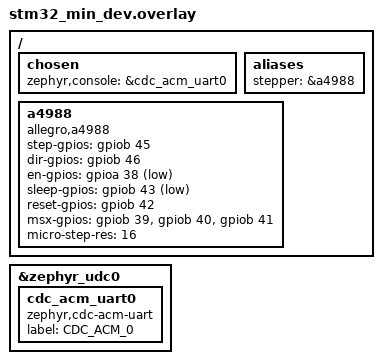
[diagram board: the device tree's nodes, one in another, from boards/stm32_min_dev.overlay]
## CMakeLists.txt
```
# SPDX-FileCopyrightText: Copyright (c) 2025 Marvin Ouma
# SPDX-License-Identifier: Apache-2.0

cmake_minimum_required(VERSION 3.20.0)

find_package(Zephyr REQUIRED HINTS $ENV{ZEPHYR_BASE})
project(a4988)

FILE(GLOB app_sources src/*.c)
target_sources(app PRIVATE ${app_sources})
```

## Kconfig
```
# SPDX-FileCopyrightText: Copyright (c) 2025 Marvin Ouma
# SPDX-License-Identifier: Apache-2.0

mainmenu "A4988 sample application"

config STEPS_PER_REV
       int "Steps per revolution"
       default 200


source "Kconfig.zephyr"
```

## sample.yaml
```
sample:
  name: A4988 Stepper Sample

tests:
  sample.stepper.a4988:
    harness: stepper
    tags: stepper
```

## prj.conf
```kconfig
CONFIG_STDOUT_CONSOLE=y
CONFIG_USB_DEVICE_STACK=y
CONFIG_USB_DEVICE_PRODUCT="Zephyr CDC ACM sample"
CONFIG_USB_DEVICE_PID=0x0001
CONFIG_LOG=y
CONFIG_USB_DRIVER_LOG_LEVEL_ERR=y
CONFIG_USB_DEVICE_LOG_LEVEL_ERR=y
CONFIG_SERIAL=y
CONFIG_UART_INTERRUPT_DRIVEN=y
CONFIG_UART_LINE_CTRL=y
CONFIG_USB_DEVICE_INITIALIZE_AT_BOOT=n

CONFIG_STEPPER=y
CONFIG_STEP_DIR_STEPPER_COUNTER_TIMING=y
```

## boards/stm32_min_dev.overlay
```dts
/ {

	chosen {
	       zephyr,console=&cdc_acm_uart0;
	};

	aliases {
		stepper = &a4988;
	};

	a4988: a4988 {
		compatible = "allegro,a4988";
		status = "okay";

		step-gpios = <&gpiob 45 GPIO_ACTIVE_HIGH>;
		dir-gpios = <&gpiob 46 GPIO_ACTIVE_HIGH>;
		en-gpios = <&gpioa 38 GPIO_ACTIVE_LOW>;
		sleep-gpios = <&gpiob 43 GPIO_ACTIVE_LOW>;
		reset-gpios = <&gpiob 42 GPIO_ACTIVE_HIGH>;
		msx-gpios = <&gpiob 39 GPIO_ACTIVE_HIGH>,
		            <&gpiob 40 GPIO_ACTIVE_HIGH>,
		            <&gpiob 41 GPIO_ACTIVE_HIGH>;
		micro-step-res = <16>;
	};
};

&zephyr_udc0 {
	     cdc_acm_uart0: cdc_acm_uart0 {
	     	compatible = "zephyr,cdc-acm-uart";
		label = "CDC_ACM_0";
	     };
};
```

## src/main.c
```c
/*
 * SPDX-FileCopyrightText: Copyright (c) 2025 Marvin Ouma
 * SPDX-License-Identifier: Apache-2.0
 */

#include <zephyr/device.h>
#include <zephyr/drivers/gpio.h>
#include <zephyr/drivers/stepper.h>
#include <zephyr/drivers/uart.h>
#include <zephyr/kernel.h>
#include <zephyr/usb/usb_device.h>
#include <zephyr/sys/printk.h>
#include <zephyr/drivers/stepper/stepper_trinamic.h>

#include <zephyr/logging/log.h>
LOG_MODULE_REGISTER(a4988log);

const struct device *stepper = DEVICE_DT_GET(DT_ALIAS(stepper));
const struct device *const console = DEVICE_DT_GET(DT_CHOSEN(zephyr_console));
uint32_t dtr = 0;

int32_t ping_pong_target_position =
	CONFIG_STEPS_PER_REV * 1 * DT_PROP(DT_ALIAS(stepper), micro_step_res);

K_SEM_DEFINE(steps_completed_sem, 0, 1);

void stepper_callback(const struct device *dev, const enum stepper_event event, void *user_data)
{
	switch (event) {
	case STEPPER_EVENT_STEPS_COMPLETED:
		k_sem_give(&steps_completed_sem);
		break;
	default:
		break;
	}
}

int main(void)
{
	if (usb_enable(NULL)) {
		return 0;
	}

	while (!dtr) {
		uart_line_ctrl_get(console, UART_LINE_CTRL_DTR, &dtr);
		k_sleep(K_MSEC(100));
	}

	LOG_INF("Starting A4988 stepper sample");
	if (!device_is_ready(stepper)) {
		LOG_INF("Device %s is not ready", stepper->name);
		return 0;
	}
	LOG_INF("stepper is %p, name is %s", stepper, stepper->name);
	LOG_INF("target position %d", ping_pong_target_position);
	stepper_set_event_callback(stepper, stepper_callback, NULL);
	stepper_enable(stepper, true);
	stepper_set_reference_position(stepper, 0);
	stepper_set_microstep_interval(stepper, 200);
	stepper_move_by(stepper, ping_pong_target_position);

	for (;;) {
		if (k_sem_take(&steps_completed_sem, K_FOREVER) == 0) {
			ping_pong_target_position = 1;
			stepper_run(stepper, 1);
		}
	}
	return 0;
}
```
